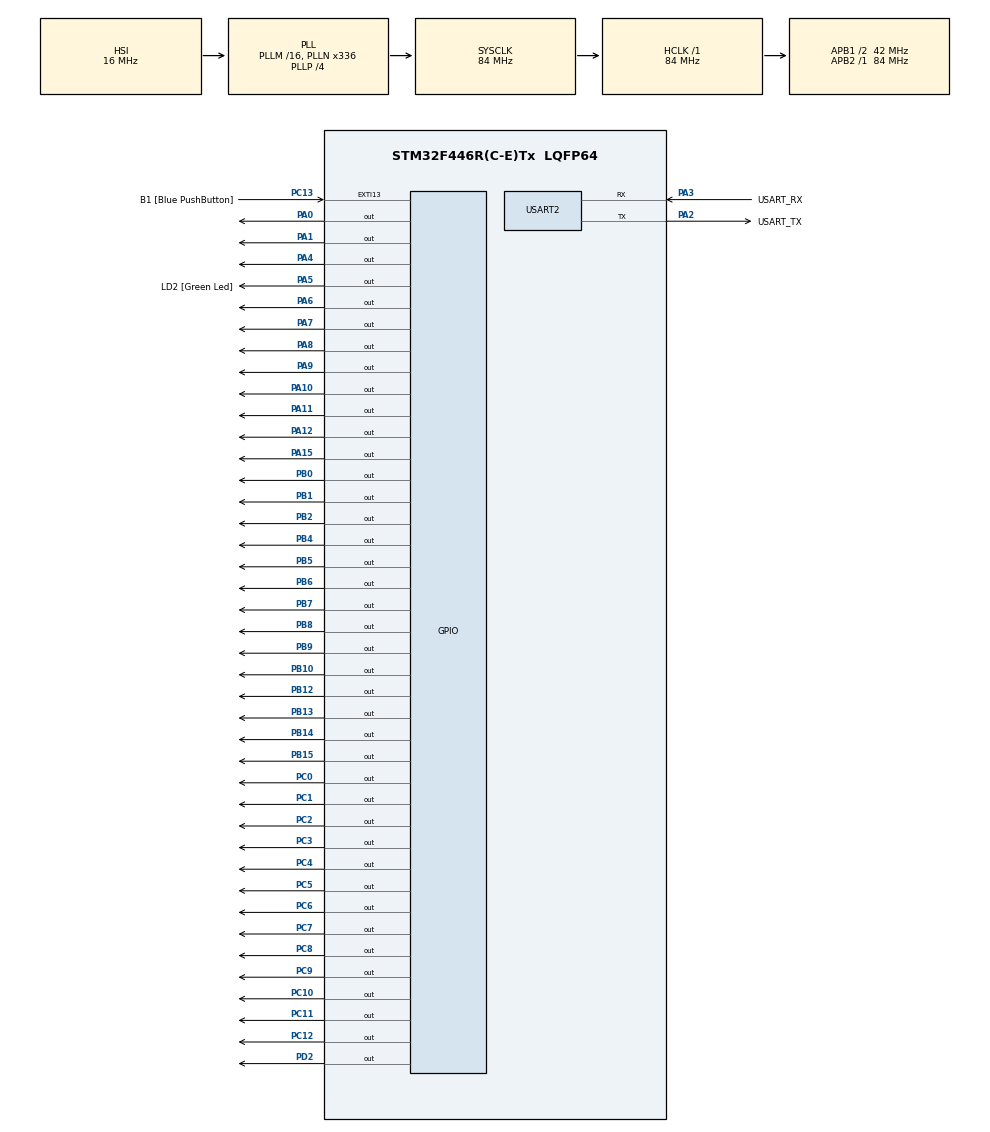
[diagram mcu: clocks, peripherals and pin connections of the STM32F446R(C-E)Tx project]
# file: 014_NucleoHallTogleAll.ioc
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Mcu.Family=STM32F4
PH0-OSC_IN.Signal=RCC_OSC_IN
RCC.CortexFreq_Value=84000000
PC12.Signal=GPIO_Output
PC10.Signal=GPIO_Output
PA14.GPIO_Label=TCK
PC13.GPIO_Label=B1 [Blue PushButton]
PB15.Signal=GPIO_Output
PB13.Signal=GPIO_Output
RCC.SYSCLKSource=RCC_SYSCLKSOURCE_PLLCLK
ProjectManager.StackSize=0x400
PA12.Signal=GPIO_Output
RCC.HCLKFreq_Value=84000000
RCC.APB2TimFreq_Value=84000000
PB6.Signal=GPIO_Output
PC7.Signal=GPIO_Output
PC3.Signal=GPIO_Output
RCC.AHBFreq_Value=84000000
PH0-OSC_IN.Mode=HSE-External-Oscillator
RCC.HSE_VALUE=8000000
PB2.Signal=GPIO_Output
PC14-OSC32_IN.Mode=LSE-External-Oscillator
PA14.Mode=Serial_Wire
PB7.Signal=GPIO_Output
PA8.Signal=GPIO_Output
RCC.FLatency-AdvancedSettings=FLASH_LATENCY_2
PH1-OSC_OUT.Mode=HSE-External-Oscillator
Mcu.Package=LQFP64
PB9.Signal=GPIO_Output
PB1.Signal=GPIO_Output
PA6.Signal=GPIO_Output
USART2.VirtualMode=VM_ASYNC
PA2.GPIO_Label=USART_TX
PA10.Signal=GPIO_Output
PA15.Signal=GPIO_Output
RCC.APB1TimFreq_Value=84000000
PC5.Signal=GPIO_Output
PB4.Signal=GPIO_Output
PA3.Signal=USART2_RX
PB3.GPIO_Label=SWO
PC15-OSC32_OUT.Mode=LSE-External-Oscillator
PC11.Signal=GPIO_Output
PC13.Signal=GPXTI13
PC8.Signal=GPIO_Output
PC2.Signal=GPIO_Output
PC4.Signal=GPIO_Output
PC6.Signal=GPIO_Output
PC0.Signal=GPIO_Output
RCC.APB1CLKDivider=RCC_HCLK_DIV2
PC14-OSC32_IN.Signal=RCC_OSC32_IN
PA0-WKUP.Signal=GPIO_Output
PA3.Mode=Asynchronous
PA13.Signal=SYS_JTMS-SWDIO
ProjectManager.TargetToolchain=STM32CubeIDE
PA9.Signal=GPIO_Output
RCC.USBFreq_Value=168000000
PC15-OSC32_OUT.Signal=RCC_OSC32_OUT
PA1.Signal=GPIO_Output
PB10.Signal=GPIO_Output
PB14.Signal=GPIO_Output
PA5.Signal=GPIO_Output
board=NUCLEO-F446RE
RCC.VCOOutputFreq_Value=336000000
RCC.APB2Freq_Value=84000000
PH1-OSC_OUT.Signal=RCC_OSC_OUT
PA13.Mode=Serial_Wire
Mcu.Name=STM32F446R(C-E)Tx
PA2.Signal=USART2_TX
PA13.GPIO_Label=TMS
RCC.48MHZClocksFreq_Value=84000000
PB3.Signal=SYS_JTDO-SWO
PA4.Signal=GPIO_Output
RCC.SYSCLKFreq_VALUE=84000000
PB5.Signal=GPIO_Output
PA5.GPIO_Label=LD2 [Green Led]
PC13.GPIO_ModeDefaultEXTI=GPIO_MODE_IT_FALLING
PA11.Signal=GPIO_Output
PA14.Signal=SYS_JTCK-SWCLK
ProjectManager.HeapSize=0x200
RCC.HSI_VALUE=16000000
RCC.PLLP=RCC_PLLP_DIV4
NVIC.PriorityGroup=NVIC_PRIORITYGROUP_0
RCC.PLLN=336
PA2.Mode=Asynchronous
PB8.Signal=GPIO_Output
PC9.Signal=GPIO_Output
PD2.Signal=GPIO_Output
RCC.APB1Freq_Value=42000000
PB0.Signal=GPIO_Output
PC1.Signal=GPIO_Output
PB12.Signal=GPIO_Output
PA3.GPIO_Label=USART_RX
PA7.Signal=GPIO_Output

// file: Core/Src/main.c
/* USER CODE BEGIN Header
 *  * Проект дрыгания ВСЕМИ ножками одновременно
 * НЕ ТРОГАТЬ! */
/**
  ******************************************************************************
  * @file           : main.c
  * @brief          : Main program body
  ******************************************************************************
  * @attention
  *
  * <h2><center>&copy; Copyright (c) 2021 STMicroelectronics.
  * All rights reserved.</center></h2>
  *
  * This software component is licensed by ST under BSD 3-Clause license,
  * the "License"; You may not use this file except in compliance with the
  * License. You may obtain a copy of the License at:
  *                        opensource.org/licenses/BSD-3-Clause
  *
  ******************************************************************************
  */
/* USER CODE END Header */
#include "main.h"

UART_HandleTypeDef huart2;

void SystemClock_Config(void);
static void MX_GPIO_Init(void);
static void MX_USART2_UART_Init(void);

int main(void)
{

  /* MCU Configuration--------------------------------------------------------*/

  /* Reset of all peripherals, Initializes the Flash interface and the Systick. */
  HAL_Init();

  /* Configure the system clock */
  SystemClock_Config();

  /* Initialize all configured peripherals */
  MX_GPIO_Init();
  MX_USART2_UART_Init();

  /* Infinite loop */
  /* USER CODE BEGIN WHILE */
  while (1)
  {
//	  HAL_GPIO_TogglePin(GPIOA, GPIO_PIN_5);

	  HAL_GPIO_TogglePin(GPIOC, GPIO_PIN_0|GPIO_PIN_1|GPIO_PIN_2|GPIO_PIN_3
	                           |GPIO_PIN_4|GPIO_PIN_5|GPIO_PIN_6|GPIO_PIN_7
	                           |GPIO_PIN_8|/*GPIO_PIN_9|*/GPIO_PIN_10|GPIO_PIN_11
	                           |GPIO_PIN_12);

	  HAL_GPIO_TogglePin(GPIOA, GPIO_PIN_0|GPIO_PIN_1|GPIO_PIN_4|LD2_Pin
	                           |GPIO_PIN_6|GPIO_PIN_7|GPIO_PIN_8|GPIO_PIN_9
	                           |GPIO_PIN_10|GPIO_PIN_11|GPIO_PIN_12|GPIO_PIN_15);

	  HAL_GPIO_TogglePin(GPIOB, GPIO_PIN_0|GPIO_PIN_1|GPIO_PIN_2|GPIO_PIN_10
	                           |GPIO_PIN_12|GPIO_PIN_13|GPIO_PIN_14|GPIO_PIN_15
	                           |GPIO_PIN_4|GPIO_PIN_5|GPIO_PIN_6|GPIO_PIN_7
	                           |GPIO_PIN_8|GPIO_PIN_9);
	  HAL_GPIO_TogglePin(GPIOD, GPIO_PIN_2);

	  	  HAL_Delay(50);

    /* USER CODE END WHILE */

  }
}

void SystemClock_Config(void)
{
  RCC_OscInitTypeDef RCC_OscInitStruct = {0};
  RCC_ClkInitTypeDef RCC_ClkInitStruct = {0};

  /** Configure the main internal regulator output voltage
  */
  __HAL_RCC_PWR_CLK_ENABLE();
  __HAL_PWR_VOLTAGESCALING_CONFIG(PWR_REGULATOR_VOLTAGE_SCALE3);
  /** Initializes the RCC Oscillators according to the specified parameters
  * in the RCC_OscInitTypeDef structure.
  */
  RCC_OscInitStruct.OscillatorType = RCC_OSCILLATORTYPE_HSI;
  RCC_OscInitStruct.HSIState = RCC_HSI_ON;
  RCC_OscInitStruct.HSICalibrationValue = RCC_HSICALIBRATION_DEFAULT;
  RCC_OscInitStruct.PLL.PLLState = RCC_PLL_ON;
  RCC_OscInitStruct.PLL.PLLSource = RCC_PLLSOURCE_HSI;
  RCC_OscInitStruct.PLL.PLLM = 16;
  RCC_OscInitStruct.PLL.PLLN = 336;
  RCC_OscInitStruct.PLL.PLLP = RCC_PLLP_DIV4;
  RCC_OscInitStruct.PLL.PLLQ = 2;
  RCC_OscInitStruct.PLL.PLLR = 2;
  if (HAL_RCC_OscConfig(&RCC_OscInitStruct) != HAL_OK)
  {
    Error_Handler();
  }
  /** Initializes the CPU, AHB and APB buses clocks
  */
  RCC_ClkInitStruct.ClockType = RCC_CLOCKTYPE_HCLK|RCC_CLOCKTYPE_SYSCLK
                              |RCC_CLOCKTYPE_PCLK1|RCC_CLOCKTYPE_PCLK2;
  RCC_ClkInitStruct.SYSCLKSource = RCC_SYSCLKSOURCE_PLLCLK;
  RCC_ClkInitStruct.AHBCLKDivider = RCC_SYSCLK_DIV1;
  RCC_ClkInitStruct.APB1CLKDivider = RCC_HCLK_DIV2;
  RCC_ClkInitStruct.APB2CLKDivider = RCC_HCLK_DIV1;

  if (HAL_RCC_ClockConfig(&RCC_ClkInitStruct, FLASH_LATENCY_2) != HAL_OK)
  {
    Error_Handler();
  }
}

static void MX_USART2_UART_Init(void)
{

  huart2.Instance = USART2;
  huart2.Init.BaudRate = 115200;
  huart2.Init.WordLength = UART_WORDLENGTH_8B;
  huart2.Init.StopBits = UART_STOPBITS_1;
  huart2.Init.Parity = UART_PARITY_NONE;
  huart2.Init.Mode = UART_MODE_TX_RX;
  huart2.Init.HwFlowCtl = UART_HWCONTROL_NONE;
  huart2.Init.OverSampling = UART_OVERSAMPLING_16;
  if (HAL_UART_Init(&huart2) != HAL_OK)
  {
    Error_Handler();
  }

}

static void MX_GPIO_Init(void)
{
  GPIO_InitTypeDef GPIO_InitStruct = {0};

  /* GPIO Ports Clock Enable */
  __HAL_RCC_GPIOC_CLK_ENABLE();
  __HAL_RCC_GPIOH_CLK_ENABLE();
  __HAL_RCC_GPIOA_CLK_ENABLE();
  __HAL_RCC_GPIOB_CLK_ENABLE();
  __HAL_RCC_GPIOD_CLK_ENABLE();

  /*Configure GPIO pin Output Level */
  HAL_GPIO_WritePin(GPIOC, GPIO_PIN_0|GPIO_PIN_1|GPIO_PIN_2|GPIO_PIN_3
                          |GPIO_PIN_4|GPIO_PIN_5|GPIO_PIN_6|GPIO_PIN_7
                          |GPIO_PIN_8|GPIO_PIN_9|GPIO_PIN_10|GPIO_PIN_11
                          |GPIO_PIN_12, GPIO_PIN_RESET);

  /*Configure GPIO pin Output Level */
  HAL_GPIO_WritePin(GPIOA, GPIO_PIN_0|GPIO_PIN_1|GPIO_PIN_4|LD2_Pin
                          |GPIO_PIN_6|GPIO_PIN_7|GPIO_PIN_8|GPIO_PIN_9
                          |GPIO_PIN_10|GPIO_PIN_11|GPIO_PIN_12|GPIO_PIN_15, GPIO_PIN_RESET);

  /*Configure GPIO pin Output Level */
  HAL_GPIO_WritePin(GPIOB, GPIO_PIN_0|GPIO_PIN_1|GPIO_PIN_2|GPIO_PIN_10
                          |GPIO_PIN_12|GPIO_PIN_13|GPIO_PIN_14|GPIO_PIN_15
                          |GPIO_PIN_4|GPIO_PIN_5|GPIO_PIN_6|GPIO_PIN_7
                          |GPIO_PIN_8|GPIO_PIN_9, GPIO_PIN_RESET);

  /*Configure GPIO pin Output Level */
  HAL_GPIO_WritePin(GPIOD, GPIO_PIN_2, GPIO_PIN_RESET);

  /*Configure GPIO pin : B1_Pin */
  GPIO_InitStruct.Pin = B1_Pin;
  GPIO_InitStruct.Mode = GPIO_MODE_IT_FALLING;
  GPIO_InitStruct.Pull = GPIO_NOPULL;
  HAL_GPIO_Init(B1_GPIO_Port, &GPIO_InitStruct);

  /*Configure GPIO pins : PC0 PC1 PC2 PC3
                           PC4 PC5 PC6 PC7
                           PC8 PC9 PC10 PC11
                           PC12 */
  GPIO_InitStruct.Pin = GPIO_PIN_0|GPIO_PIN_1|GPIO_PIN_2|GPIO_PIN_3
                          |GPIO_PIN_4|GPIO_PIN_5|GPIO_PIN_6|GPIO_PIN_7
                          |GPIO_PIN_8|GPIO_PIN_9|GPIO_PIN_10|GPIO_PIN_11
                          |GPIO_PIN_12;
  GPIO_InitStruct.Mode = GPIO_MODE_OUTPUT_PP;
  GPIO_InitStruct.Pull = GPIO_NOPULL;
  GPIO_InitStruct.Speed = GPIO_SPEED_FREQ_LOW;
  HAL_GPIO_Init(GPIOC, &GPIO_InitStruct);

  /*Configure GPIO pins : PA0 PA1 PA4 LD2_Pin
                           PA6 PA7 PA8 PA9
                           PA10 PA11 PA12 PA15 */
  GPIO_InitStruct.Pin = GPIO_PIN_0|GPIO_PIN_1|GPIO_PIN_4|LD2_Pin
                          |GPIO_PIN_6|GPIO_PIN_7|GPIO_PIN_8|GPIO_PIN_9
                          |GPIO_PIN_10|GPIO_PIN_11|GPIO_PIN_12|GPIO_PIN_15;
  GPIO_InitStruct.Mode = GPIO_MODE_OUTPUT_PP;
  GPIO_InitStruct.Pull = GPIO_NOPULL;
  GPIO_InitStruct.Speed = GPIO_SPEED_FREQ_LOW;
  HAL_GPIO_Init(GPIOA, &GPIO_InitStruct);

  /*Configure GPIO pins : PB0 PB1 PB2 PB10
                           PB12 PB13 PB14 PB15
                           PB4 PB5 PB6 PB7
                           PB8 PB9 */
  GPIO_InitStruct.Pin = GPIO_PIN_0|GPIO_PIN_1|GPIO_PIN_2|GPIO_PIN_10
                          |GPIO_PIN_12|GPIO_PIN_13|GPIO_PIN_14|GPIO_PIN_15
                          |GPIO_PIN_4|GPIO_PIN_5|GPIO_PIN_6|GPIO_PIN_7
                          |GPIO_PIN_8|GPIO_PIN_9;
  GPIO_InitStruct.Mode = GPIO_MODE_OUTPUT_PP;
  GPIO_InitStruct.Pull = GPIO_NOPULL;
  GPIO_InitStruct.Speed = GPIO_SPEED_FREQ_LOW;
  HAL_GPIO_Init(GPIOB, &GPIO_InitStruct);

  /*Configure GPIO pin : PD2 */
  GPIO_InitStruct.Pin = GPIO_PIN_2;
  GPIO_InitStruct.Mode = GPIO_MODE_OUTPUT_PP;
  GPIO_InitStruct.Pull = GPIO_NOPULL;
  GPIO_InitStruct.Speed = GPIO_SPEED_FREQ_LOW;
  HAL_GPIO_Init(GPIOD, &GPIO_InitStruct);

}

void Error_Handler(void)
{
  __disable_irq();
  while (1)
  {
  }
}

/************************ (C) COPYRIGHT STMicroelectronics *****END OF FILE****/
